# PIC32MX430F064L device description
Architecture: MIPS; Family: PIC32MX; Series: PIC32MX
Registers are 32-bit, read-write, no defined reset value unless marked. A register's access mark holds for its fields unless they carry their own. Offsets are from the block's base; [hi:lo] are bit positions; {n}, {i} and the like mark numbered series; 'fields as' and 'values as' point back to an identical list.

## RTCC
Instances: RTCC 0x1f800200 in periph0
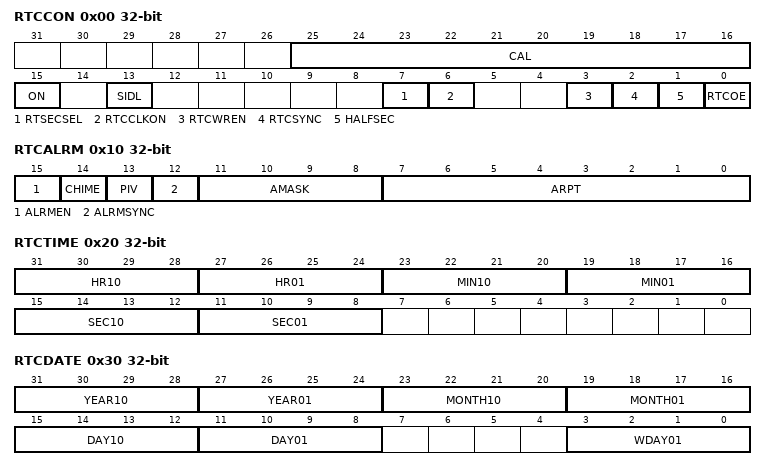
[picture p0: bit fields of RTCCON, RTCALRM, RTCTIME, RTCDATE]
0x00 RTCCON — RTC Control Register
  [25:16] CAL — RTC Drift Calibration bits
    0x1ff=Maximum positive adjustment; 1=Minimum positive adjustment; 0=No adjustment; 0x3ff=Minimum negative adjustment; 0x200=Maximum negative adjustment
  [15] ON — RTCC On bit
    1=RTCC module is enabled; 0=RTCC module is disabled
  [13] SIDL — Stop in Idle Mode bit
    1=Disables the PBCLK to the RTCC when CPU enters in Idle mode; 0=Continue normal operation in Idle mode
  [7] RTSECSEL — RTCC Seconds Clock Output Select bit
    1=RTCC Seconds Clock is selected for the RTCC pin; 0=RTCC Alarm Pulse is selected for the RTCC pin
  [6] RTCCLKON — RTCC Clock Enable Status bit
    1=RTCC Clock is actively running; 0=RTCC Clock is not running
  [3] RTCWREN — RTC Value Registers Write Enable bit
    1=RTC Value registers can be written to by the user; 0=RTC Value registers are locked out from being written to by the user
  [2] RTCSYNC — RTCC Value Registers Read Synchronization bit
    1=RTC Value registers can change while reading due to a rollover ripple that results in an invalid data read; 0=RTC Value registers can be read without concern about a rollover ripple
  [1] HALFSEC — Half-Second Status bit
    1=Second half period of a second; 0=First half period of a second
  [0] RTCOE — RTCC Output Enable bit
    1=RTCC clock output is enabled clock presented onto an I/O; 0=RTCC clock output is disabled
0x10 RTCALRM — RTC ALARM Control Register
  [15] ALRMEN — Alarm Enable bit
    1=Alarm is enabled; 0=Alarm is disabled
  [14] CHIME — Chime Enable bit
    1=Chime is enabled ARPT(7:0) is allowed to rollover from 0x00 to 0xFF; 0=Chime is disabled ARPT(7:0) stops once it reaches 0x00
  [13] PIV — Alarm Pulse Initial Value bit
    1=(When ALRMEN = 0) Alarm pulse high / (When ALRMEN = 1) PIV is read-only and returns state of the alarm pulse; 0=(When ALRMEN = 0) Alarm pulse low / (When ALRMEN = 1) PIV is read-only and returns state of the alarm pulse
  [12] ALRMSYNC — Alarm Sync bit
    1=ARPT(7:0) and ALRMEN may change as a result of a half second rollover during a read; 0=ARPT(7:0) and ALRMEN can be read without concerns of rollover because the prescaler is > 32 RTC clocks away from a half-second rollover
  [11:8] AMASK — Alarm Mask Configuration bits
    0=Every half-second; 1=Every second; 2=Every 10 seconds; 3=Every minute; 4=Every 10 minutes; 5=Every hour; 6=Once a day; 7=Once a week; 8=Once a month; 9=Once a year (except when configured for February 29; {v}=Reserved; do not use (v=10..15)
  [7:0] ARPT — Alarm Repeat Counter Value bits
    {v}=Alarm will trigger {v+1} times (v=0..255)
0x20 RTCTIME — RTC Time Value Register
  [31:28] HR10, [27:24] HR01, [23:20] MIN10, [19:16] MIN01, [15:12] SEC10, [11:8] SEC01
0x30 RTCDATE — RTC Date Value Register
  [31:28] YEAR10, [27:24] YEAR01, [23:20] MONTH10, [19:16] MONTH01, [15:12] DAY10, [11:8] DAY01, [3:0] WDAY01
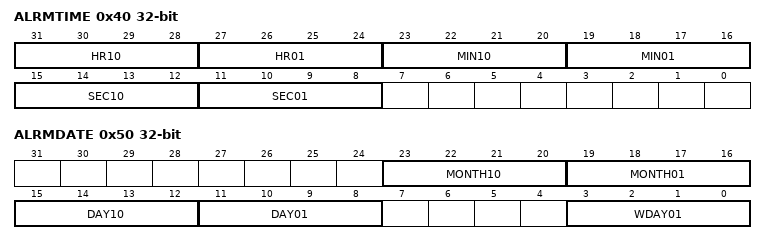
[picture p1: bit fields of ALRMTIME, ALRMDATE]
0x40 ALRMTIME — Alarm Time Value Register
  fields as RTCTIME
0x50 ALRMDATE — Alarm Date Value Register
  [23:20] MONTH10, [19:16] MONTH01, [15:12] DAY10, [11:8] DAY01, [3:0] WDAY01

## TMR1
Instances: TMR1 0x1f800600 in periph0
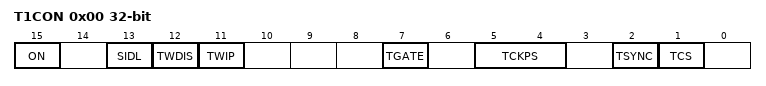
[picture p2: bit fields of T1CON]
0x00 T1CON — TYPE A TIMER CONTROL REGISTER
  [15] ON — Timer On bit
    1=Timer is enabled; 0=Timer is disabled
  [13] SIDL — Stop in Idle Mode bit
    1=Discontinue operation when device enters Idle mode; 0=Continue operation even in Idle mode
  [12] TWDIS — Asynchronous Timer Write Disable bit
    1=Writes to TMR1 are ignored until pending write operation completes; 0=Back-to-back writes are enabled (Legacy Asynchronous Timer functionality)
  [11] TWIP — Asynchronous Timer Write in Progress bit
    1=(In Asynchronous Timer mode) Asynchronous write to TMR1 register in progress / (in synchronous mode) read as 0; 0=(In Asynchronous Timer mode) Asynchronous write to TMR1 register complete / (in synchronous mode) read as 0
  [7] TGATE — Timer Gated Time Accumulation Enable bit
    1=(When TCS is 0) Gated time accumulation is enabled / (When TCS is 1) bit is ignored; 0=(When TCS is 0) Gated time accumulation is disabled / (When TCS is 1) bit is ignored
  [5:4] TCKPS — Timer Input Clock Prescale Select bits
    3=1:256 prescale value; 2=1:64 prescale value; 1=1:8 prescale value; 0=1:1 prescale value
  [2] TSYNC — Timer External Clock Input Synchronization Selection bit
    1=(When TCS is 1) External clock input is synchronized / (When TCS is 0) bit is ignored; 0=(When TCS is 1) External clock input is not synchronized / (When TCS is 0) bit is ignored
  [1] TCS — Timer Clock Source Select bit
    1=External clock from T1CKI pin; 0=Internal peripheral clock
0x10 TMR1
0x20 PR1

## TMR
Instances: TMR 0x1f800800 in periph0
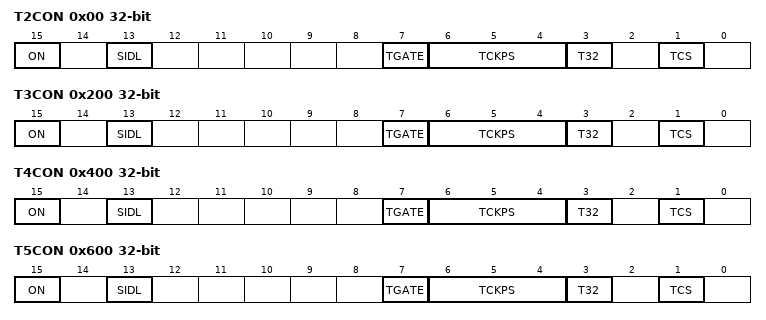
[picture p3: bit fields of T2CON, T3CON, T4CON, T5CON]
0x00 T2CON — Type B Timer Control Register
  [15] ON — Timer On bit
    1=Module is enabled; 0=Module is disabled
  [13] SIDL — Stop in Idle Mode bit
    1=Discontinue operation when device enters Idle mode; 0=Continue operation even in Idle mode
  [7] TGATE — Timer Gated Time Accumulation Enable bit
    1=(When TCS is 1): Gated time accumulation is enabled / (When TCS=0): bit is ignored and read as 0; 0=(When TCS is 0): Gated time accumulation is disabled / (When TCS=0): bit is ignored and read as 0
  [6:4] TCKPS — Timer Input Clock Prescale Select bits
    7=1:256 prescale value; 6=1:64 prescale value; 5=1:32 prescale value; 4=1:16 prescale value; 3=1:8 prescale value; 2=1:4 prescale value; 1=1:2 prescale value; 0=1:1 prescale value
  [3] T32 — 32-Bit Timer Mode Select bit
    1=Odd numbered and even numbered timers form a 32-bit timer; 0=Odd numbered and even numbered timers form separate 16-bit timers
  [1] TCS — Timer Clock Source Select bit
    1=External clock from TxCK pin; 0=Internal peripheral clock
0x10 TMR2
0x20 PR2
0x200 T3CON — Type B Timer Control Register
  fields as T2CON
0x210 TMR3
0x220 PR3
0x400 T4CON — Type B Timer Control Register
  fields as T2CON
0x410 TMR4
0x420 PR4
0x600 T5CON — Type B Timer Control Register
  fields as T2CON
0x610 TMR5
0x620 PR5

## TRAA_Ports
Instances: TRAA_Ports 0x1f80fa04 in periph1
0x00 INT1R — Peripheral Pin Select Output Register
  [3:0] INT1R
0x04 INT2R — Peripheral Pin Select Output Register
  [3:0] INT2R
0x08 INT3R — Peripheral Pin Select Output Register
  [3:0] INT3R
0x0C INT4R — Peripheral Pin Select Output Register
  [3:0] INT4R
{0xC+4i} T{i}CKR (i=2..5) — Peripheral Pin Select Output Register
  [3:0] T{i}CKR
{0x20+4i} IC{i}R (i=1..5) — Peripheral Pin Select Output Register
  [3:0] IC{i}R
0x44 OCFAR — Peripheral Pin Select Output Register
  [3:0] OCFAR
{0x44+8i} U{i}RXR (i=1..5) — Peripheral Pin Select Output Register
  [3:0] U{i}RXR
{0x48+8i} U{i}CTSR (i=1..5) — Peripheral Pin Select Output Register
  [3:0] U{i}CTSR
0x80 SDI1R — Peripheral Pin Select Output Register
  [3:0] SDI1R
0x84 SS1R — Peripheral Pin Select Output Register
  [3:0] SS1R
0x8C SDI2R — Peripheral Pin Select Output Register
  [3:0] SDI2R
0x90 SS2R — Peripheral Pin Select Output Register
  [3:0] SS2R
0xCC REFCLKIR — Peripheral Pin Select Output Register
  [3:0] REFCLKIR

## WDT
Instances: WDT 0x1f800000 in periph0
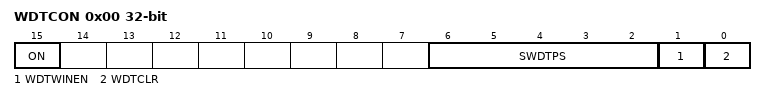
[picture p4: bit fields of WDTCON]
0x00 WDTCON — Watchdog Timer Control Register
  [15] ON — Watchdog Timer Enable bit
    1=Enables the WDT if it is not enabled by the device configuration; 0=Disable the WDT if it was enabled in software
  [6:2] SWDTPS
  [1] WDTWINEN — Watchdog Timer Window Enable bit
    1=Enable windowed Watchdog Timer; 0=Disable windowed Watchdog Timer
  [0] WDTCLR — Watchdog Timer Reset bit
    1=Writing a 1 will clear the WDT; 0=Software cannot force this bit to a 0
